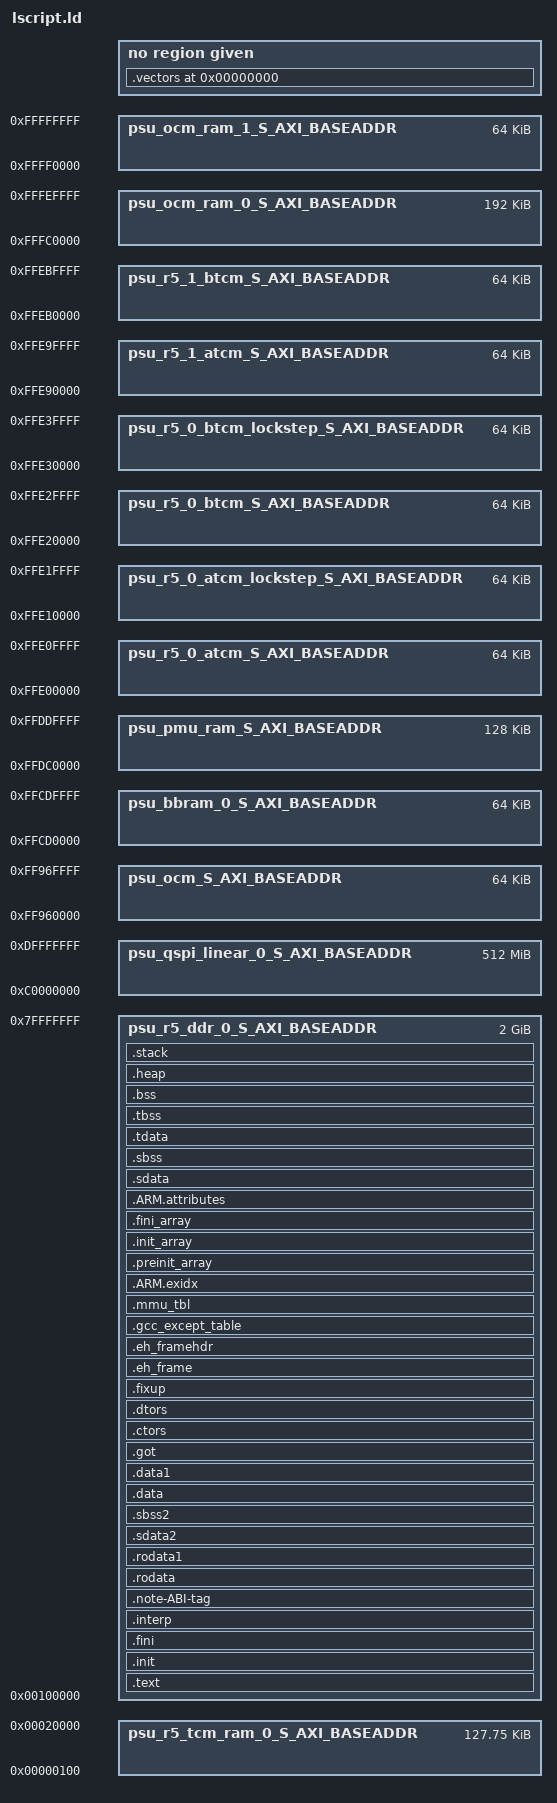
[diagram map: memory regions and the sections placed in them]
/*******************************************************************/
/*                                                                 */
/* This file is automatically generated by linker script generator.*/
/*                                                                 */
/* Version:                                 */
/*                                                                 */
/* Copyright (c) 2010 Xilinx, Inc.  All rights reserved.           */
/*                                                                 */
/* Description : ARM-v7 Linker Script                          */
/*                                                                 */
/*******************************************************************/

_STACK_SIZE = DEFINED(_STACK_SIZE) ? _STACK_SIZE : 0x2000;
_HEAP_SIZE = DEFINED(_HEAP_SIZE) ? _HEAP_SIZE : 0x2000;

_ABORT_STACK_SIZE = DEFINED(_ABORT_STACK_SIZE) ? _ABORT_STACK_SIZE : 1024;
_SUPERVISOR_STACK_SIZE = DEFINED(_SUPERVISOR_STACK_SIZE) ? _SUPERVISOR_STACK_SIZE : 2048;
_IRQ_STACK_SIZE = DEFINED(_IRQ_STACK_SIZE) ? _IRQ_STACK_SIZE : 1024;
_FIQ_STACK_SIZE = DEFINED(_FIQ_STACK_SIZE) ? _FIQ_STACK_SIZE : 1024;
_UNDEF_STACK_SIZE = DEFINED(_UNDEF_STACK_SIZE) ? _UNDEF_STACK_SIZE : 1024;

/* Define Memories in the system */

MEMORY
{
   psu_bbram_0_S_AXI_BASEADDR : ORIGIN = 0xFFCD0000, LENGTH = 0x10000
   psu_ocm_S_AXI_BASEADDR : ORIGIN = 0xFF960000, LENGTH = 0x10000
   psu_ocm_ram_0_S_AXI_BASEADDR : ORIGIN = 0xFFFC0000, LENGTH = 0x30000
   psu_ocm_ram_1_S_AXI_BASEADDR : ORIGIN = 0xFFFF0000, LENGTH = 0x10000
   psu_pmu_ram_S_AXI_BASEADDR : ORIGIN = 0xFFDC0000, LENGTH = 0x20000
   psu_qspi_linear_0_S_AXI_BASEADDR : ORIGIN = 0xC0000000, LENGTH = 0x20000000
   psu_r5_0_atcm_S_AXI_BASEADDR : ORIGIN = 0xFFE00000, LENGTH = 0x10000
   psu_r5_0_atcm_lockstep_S_AXI_BASEADDR : ORIGIN = 0xFFE10000, LENGTH = 0x10000
   psu_r5_0_btcm_S_AXI_BASEADDR : ORIGIN = 0xFFE20000, LENGTH = 0x10000
   psu_r5_0_btcm_lockstep_S_AXI_BASEADDR : ORIGIN = 0xFFE30000, LENGTH = 0x10000
   psu_r5_1_atcm_S_AXI_BASEADDR : ORIGIN = 0xFFE90000, LENGTH = 0x10000
   psu_r5_1_btcm_S_AXI_BASEADDR : ORIGIN = 0xFFEB0000, LENGTH = 0x10000
   psu_r5_ddr_0_S_AXI_BASEADDR : ORIGIN = 0x100000, LENGTH = 0x7FF00000
   psu_r5_tcm_ram_0_S_AXI_BASEADDR : ORIGIN = 0x100, LENGTH = 0x1FF01
}

/* Specify the default entry point to the program */

ENTRY(_boot)

/* Define the sections, and where they are mapped in memory */

SECTIONS
{
.vectors 0x0 : {
   KEEP (*(.freertos_vectors))
   KEEP (*(.vectors))
}

.text : {
   *(.boot)
   *(.text)
   *(.text.*)
   *(.gnu.linkonce.t.*)
   *(.plt)
   *(.gnu_warning)
   *(.gcc_execpt_table)
   *(.glue_7)
   *(.glue_7t)
   *(.vfp11_veneer)
   *(.ARM.extab)
   *(.gnu.linkonce.armextab.*)
} > psu_r5_ddr_0_S_AXI_BASEADDR

.init : {
   KEEP (*(.init))
} > psu_r5_ddr_0_S_AXI_BASEADDR

.fini : {
   KEEP (*(.fini))
} > psu_r5_ddr_0_S_AXI_BASEADDR

.interp : {
   KEEP (*(.interp))
} > psu_r5_ddr_0_S_AXI_BASEADDR

.note-ABI-tag : {
   KEEP (*(.note-ABI-tag))
} > psu_r5_ddr_0_S_AXI_BASEADDR

.rodata : {
   __rodata_start = .;
   *(.rodata)
   *(.rodata.*)
   *(.gnu.linkonce.r.*)
   __rodata_end = .;
} > psu_r5_ddr_0_S_AXI_BASEADDR

.rodata1 : {
   __rodata1_start = .;
   *(.rodata1)
   *(.rodata1.*)
   __rodata1_end = .;
} > psu_r5_ddr_0_S_AXI_BASEADDR

.sdata2 : {
   __sdata2_start = .;
   *(.sdata2)
   *(.sdata2.*)
   *(.gnu.linkonce.s2.*)
   __sdata2_end = .;
} > psu_r5_ddr_0_S_AXI_BASEADDR

.sbss2 : {
   __sbss2_start = .;
   *(.sbss2)
   *(.sbss2.*)
   *(.gnu.linkonce.sb2.*)
   __sbss2_end = .;
} > psu_r5_ddr_0_S_AXI_BASEADDR

.data : {
   __data_start = .;
   *(.data)
   *(.data.*)
   *(.gnu.linkonce.d.*)
   *(.jcr)
   *(.got)
   *(.got.plt)
   __data_end = .;
} > psu_r5_ddr_0_S_AXI_BASEADDR

.data1 : {
   __data1_start = .;
   *(.data1)
   *(.data1.*)
   __data1_end = .;
} > psu_r5_ddr_0_S_AXI_BASEADDR

.got : {
   *(.got)
} > psu_r5_ddr_0_S_AXI_BASEADDR

.ctors : {
   __CTOR_LIST__ = .;
   ___CTORS_LIST___ = .;
   KEEP (*crtbegin.o(.ctors))
   KEEP (*(EXCLUDE_FILE(*crtend.o) .ctors))
   KEEP (*(SORT(.ctors.*)))
   KEEP (*(.ctors))
   __CTOR_END__ = .;
   ___CTORS_END___ = .;
} > psu_r5_ddr_0_S_AXI_BASEADDR

.dtors : {
   __DTOR_LIST__ = .;
   ___DTORS_LIST___ = .;
   KEEP (*crtbegin.o(.dtors))
   KEEP (*(EXCLUDE_FILE(*crtend.o) .dtors))
   KEEP (*(SORT(.dtors.*)))
   KEEP (*(.dtors))
   __DTOR_END__ = .;
   ___DTORS_END___ = .;
} > psu_r5_ddr_0_S_AXI_BASEADDR

.fixup : {
   __fixup_start = .;
   *(.fixup)
   __fixup_end = .;
} > psu_r5_ddr_0_S_AXI_BASEADDR

.eh_frame : {
   *(.eh_frame)
} > psu_r5_ddr_0_S_AXI_BASEADDR

.eh_framehdr : {
   __eh_framehdr_start = .;
   *(.eh_framehdr)
   __eh_framehdr_end = .;
} > psu_r5_ddr_0_S_AXI_BASEADDR

.gcc_except_table : {
   *(.gcc_except_table)
} > psu_r5_ddr_0_S_AXI_BASEADDR

.mmu_tbl (ALIGN(16384)) : {
   __mmu_tbl_start = .;
   *(.mmu_tbl)
   __mmu_tbl_end = .;
} > psu_r5_ddr_0_S_AXI_BASEADDR

.ARM.exidx : {
   __exidx_start = .;
   *(.ARM.exidx*)
   *(.gnu.linkonce.armexidix.*.*)
   __exidx_end = .;
} > psu_r5_ddr_0_S_AXI_BASEADDR

.preinit_array : {
   __preinit_array_start = .;
   KEEP (*(SORT(.preinit_array.*)))
   KEEP (*(.preinit_array))
   __preinit_array_end = .;
} > psu_r5_ddr_0_S_AXI_BASEADDR

.init_array : {
   __init_array_start = .;
   KEEP (*(SORT(.init_array.*)))
   KEEP (*(.init_array))
   __init_array_end = .;
} > psu_r5_ddr_0_S_AXI_BASEADDR

.fini_array : {
   __fini_array_start = .;
   KEEP (*(SORT(.fini_array.*)))
   KEEP (*(.fini_array))
   __fini_array_end = .;
} > psu_r5_ddr_0_S_AXI_BASEADDR

.ARM.attributes : {
   __ARM.attributes_start = .;
   *(.ARM.attributes)
   __ARM.attributes_end = .;
} > psu_r5_ddr_0_S_AXI_BASEADDR

.sdata : {
   __sdata_start = .;
   *(.sdata)
   *(.sdata.*)
   *(.gnu.linkonce.s.*)
   __sdata_end = .;
} > psu_r5_ddr_0_S_AXI_BASEADDR

.sbss (NOLOAD) : {
   __sbss_start = .;
   *(.sbss)
   *(.sbss.*)
   *(.gnu.linkonce.sb.*)
   __sbss_end = .;
} > psu_r5_ddr_0_S_AXI_BASEADDR

.tdata : {
   __tdata_start = .;
   *(.tdata)
   *(.tdata.*)
   *(.gnu.linkonce.td.*)
   __tdata_end = .;
} > psu_r5_ddr_0_S_AXI_BASEADDR

.tbss : {
   __tbss_start = .;
   *(.tbss)
   *(.tbss.*)
   *(.gnu.linkonce.tb.*)
   __tbss_end = .;
} > psu_r5_ddr_0_S_AXI_BASEADDR

.bss (NOLOAD) : {
   . = ALIGN(4);
   __bss_start__ = .;
   *(.bss)
   *(.bss.*)
   *(.gnu.linkonce.b.*)
   *(COMMON)
   . = ALIGN(4);
   __bss_end__ = .;
} > psu_r5_ddr_0_S_AXI_BASEADDR

_SDA_BASE_ = __sdata_start + ((__sbss_end - __sdata_start) / 2 );

_SDA2_BASE_ = __sdata2_start + ((__sbss2_end - __sdata2_start) / 2 );

/* Generate Stack and Heap definitions */

.heap (NOLOAD) : {
   . = ALIGN(16);
   _heap = .;
   HeapBase = .;
   _heap_start = .;
   . += _HEAP_SIZE;
   _heap_end = .;
   HeapLimit = .;
} > psu_r5_ddr_0_S_AXI_BASEADDR

.stack (NOLOAD) : {
   . = ALIGN(16);
   _stack_end = .;
   . += _STACK_SIZE;
   _stack = .;
   __stack = _stack;
   . = ALIGN(16);
   _irq_stack_end = .;
   . += _IRQ_STACK_SIZE;
   __irq_stack = .;
   _supervisor_stack_end = .;
   . += _SUPERVISOR_STACK_SIZE;
   . = ALIGN(16);
   __supervisor_stack = .;
   _abort_stack_end = .;
   . += _ABORT_STACK_SIZE;
   . = ALIGN(16);
   __abort_stack = .;
   _fiq_stack_end = .;
   . += _FIQ_STACK_SIZE;
   . = ALIGN(16);
   __fiq_stack = .;
   _undef_stack_end = .;
   . += _UNDEF_STACK_SIZE;
   . = ALIGN(16);
   __undef_stack = .;
} > psu_r5_ddr_0_S_AXI_BASEADDR

_end = .;
}

